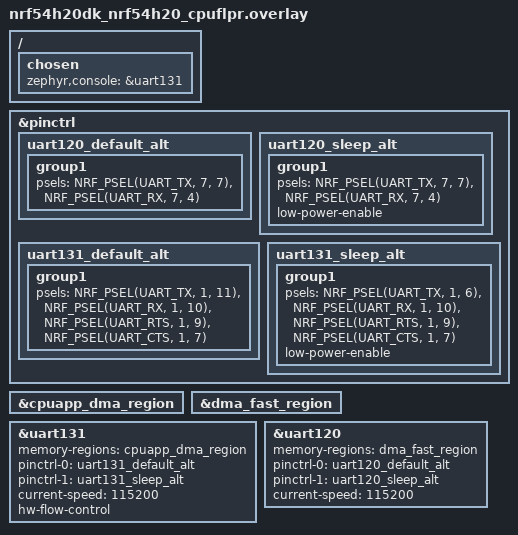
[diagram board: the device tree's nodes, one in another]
/* SPDX-License-Identifier: Apache-2.0 */

/ {
	chosen {
		zephyr,console = &uart131;
	};
};

&pinctrl {
	uart120_default_alt: uart120_default_alt {
		group1 {
			psels = <NRF_PSEL(UART_TX, 7, 7)>,
				<NRF_PSEL(UART_RX, 7, 4)>;
		};
	};

	uart120_sleep_alt: uart120_sleep_alt {
		group1 {
			psels = <NRF_PSEL(UART_TX, 7, 7)>,
				<NRF_PSEL(UART_RX, 7, 4)>;
			low-power-enable;
		};
	};

	uart131_default_alt: uart131_default_alt {
		group1 {
			psels = <NRF_PSEL(UART_TX, 1, 11)>,
				<NRF_PSEL(UART_RX, 1, 10)>,
				<NRF_PSEL(UART_RTS, 1, 9)>,
				<NRF_PSEL(UART_CTS, 1, 7)>;
		};
	};

	uart131_sleep_alt: uart131_sleep_alt {
		group1 {
			psels = <NRF_PSEL(UART_TX, 1, 6)>,
				<NRF_PSEL(UART_RX, 1, 10)>,
				<NRF_PSEL(UART_RTS, 1, 9)>,
				<NRF_PSEL(UART_CTS, 1, 7)>;
			low-power-enable;
		};
	};
};

&cpuapp_dma_region {
	status = "okay";
};

&dma_fast_region {
	status = "okay";
};

&uart131 {
	status = "okay";
	memory-regions = <&cpuapp_dma_region>;
	pinctrl-0 = <&uart131_default_alt>;
	pinctrl-1 = <&uart131_sleep_alt>;
	pinctrl-names = "default", "sleep";
	current-speed = <115200>;
	hw-flow-control;
};

dut: &uart120 {
	status = "okay";
	memory-regions = <&dma_fast_region>;
	pinctrl-0 = <&uart120_default_alt>;
	pinctrl-1 = <&uart120_sleep_alt>;
	pinctrl-names = "default", "sleep";
	current-speed = <115200>;
	/delete-property/ hw-flow-control;
};
